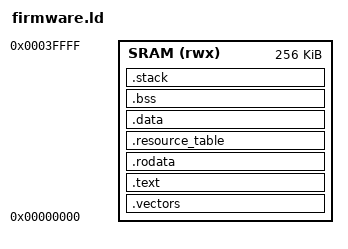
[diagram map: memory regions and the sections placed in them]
/*
 * firmware.ld - Linker script for XuanTie E907 RISC-V Firmware
 * Running in 256 KB Dedicated RISC-V SRAM (0x00000000 - 0x0003FFFF)
 */

OUTPUT_ARCH("riscv")
ENTRY(_start)

MEMORY
{
    SRAM (rwx) : ORIGIN = 0x00000000, LENGTH = 256K
}

SECTIONS
{
    /* 1. Vector table and CRT0 startup code at SRAM A2 base. */
    .vectors :
    {
        KEEP(*(.vectors))
        KEEP(*(.text.startup))
    } > SRAM

    /* 2. Program Code */
    .text :
    {
        . = ALIGN(4);
        *(.text)
        *(.text.*)
        . = ALIGN(4);
    } > SRAM

    .rodata :
    {
        . = ALIGN(4);
        *(.rodata)
        *(.rodata.*)
        . = ALIGN(4);
    } > SRAM

    /* 3. RemoteProc Resource Table */
    .resource_table :
    {
        . = ALIGN(4);
        KEEP(*(.resource_table))
        KEEP(*(.resource_table*))
        . = ALIGN(4);
    } > SRAM

    .data :
    {
        . = ALIGN(4);
        _data_start = .;
        PROVIDE(__global_pointer$ = . + 0x800);
        *(.data)
        *(.data.*)
        *(.sdata)
        *(.sdata.*)
        . = ALIGN(4);
        _data_end = .;
    } > SRAM

    /* 5. Zero-initialized BSS Segment */
    .bss :
    {
        . = ALIGN(4);
        _bss_start = .;
        *(.bss)
        *(.bss.*)
        *(.sbss)
        *(.sbss.*)
        *(COMMON)
        . = ALIGN(4);
        _bss_end = .;
    } > SRAM

    /* 6. Execution Stack (8 KB) */
    .stack (NOLOAD) :
    {
        . = ALIGN(16);
        _stack_bottom = .;
        . += 0x2000;
        _stack_top = .;
    } > SRAM

    /* Discard unwinding and metadata sections */
    /DISCARD/ :
    {
        *(.eh_frame)
        *(.eh_frame_hdr)
        *(.comment)
        *(.note.gnu.build-id)
    }
}
